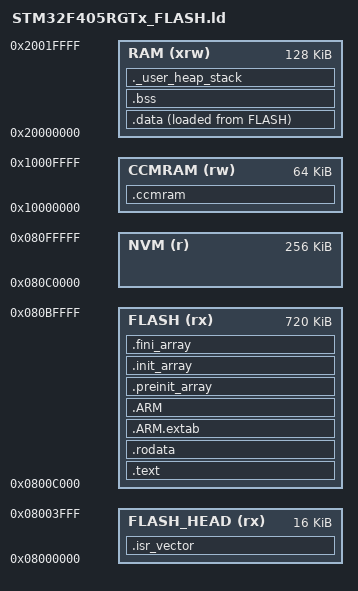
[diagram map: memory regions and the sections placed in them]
/*
*****************************************************************************
**

**  File        : LinkerScript.ld
**
**  Abstract    : Linker script for STM32F405RGTx Device with
**                1024KByte FLASH, 128KByte RAM
**
**                Set heap size, stack size and stack location according
**                to application requirements.
**
**                Set memory bank area and size if external memory is used.
**
**  Target      : STMicroelectronics STM32
**
**
**  Distribution: The file is distributed as is, without any warranty
**                of any kind.
**
**  (c)Copyright Ac6.
**  You may use this file as-is or modify it according to the needs of your
**  project. Distribution of this file (unmodified or modified) is not
**  permitted. Ac6 permit registered System Workbench for MCU users the
**  rights to distribute the assembled, compiled & linked contents of this
**  file as part of an application binary file, provided that it is built
**  using the System Workbench for MCU toolchain.
**
*****************************************************************************
*/

/* Entry Point */
ENTRY(Reset_Handler)

/* Highest address of the user mode stack */
_estack = 0x20020000;    /* end of RAM */
/* Generate a link error if heap and stack don't fit into RAM */
_Min_Heap_Size = 0x3C00;      /* required amount of heap  */
_Min_Stack_Size = 0x800; /* required amount of stack */
_heap_end_max = _estack - _Min_Stack_Size;

/* Specify the memory areas
 *
 * Flash layout no F405 (STM32F405RGT6, 1MB):
 *   sector 0  (16K)  @0x08000000 -> vetores + stub Reset_Handler (FLASH_HEAD)
 *   sector 1  (16K)  @0x08004000 -> ODrive NVM page A (config_manager hardcoded)
 *   sector 2  (16K)  @0x08008000 -> ODrive NVM page B (config_manager hardcoded)
 *   sectores 3-9    @0x0800C000..0x080BFFFF -> .text principal (FLASH)
 *   sector 10 (128K) @0x080C0000 -> FFB EEPROM emulada página 0 (NVM region)
 *   sector 11 (128K) @0x080E0000 -> FFB EEPROM emulada página 1 (NVM region)
 *
 * Phase 3.1: FFB EEPROM mudou de S1+S2 (que colidem com ODrive NVM) pra
 * S10+S11. Defines em Makefile: EEPROM_START_ADDRESS=0x080C0000, PAGE_SIZE=128K.
 */
MEMORY
{
RAM        (xrw) : ORIGIN = 0x20000000, LENGTH = 128K
CCMRAM     (rw)  : ORIGIN = 0x10000000, LENGTH = 64K
FLASH_HEAD (rx)  : ORIGIN = 0x08000000, LENGTH = 16K
FLASH      (rx)  : ORIGIN = 0x0800C000, LENGTH = 720K
NVM        (r)   : ORIGIN = 0x080C0000, LENGTH = 256K
}

/* Define output sections */
SECTIONS
{
  /* Vetores ficam sozinhos no setor 0. DFU bootloader lê SP em +0 e PC em +4. */
  .isr_vector :
  {
    . = ALIGN(4);
    KEEP(*(.isr_vector))
    . = ALIGN(4);
  } >FLASH_HEAD

  /* The program code and other data goes into FLASH */
  .text :
  {
    . = ALIGN(4);
    *(.text)           /* .text sections (code) */
    *(.text*)          /* .text* sections (code) */
    *(.glue_7)         /* glue arm to thumb code */
    *(.glue_7t)        /* glue thumb to arm code */
    *(.eh_frame)

    KEEP (*(.init))
    KEEP (*(.fini))

    . = ALIGN(4);
    _etext = .;        /* define a global symbols at end of code */
  } >FLASH

  /* Constant data goes into FLASH */
  .rodata :
  {
    . = ALIGN(4);
    *(.rodata)         /* .rodata sections (constants, strings, etc.) */
    *(.rodata*)        /* .rodata* sections (constants, strings, etc.) */
    . = ALIGN(4);
  } >FLASH

  .ARM.extab   : { *(.ARM.extab* .gnu.linkonce.armextab.*) } >FLASH
  .ARM : {
    __exidx_start = .;
    *(.ARM.exidx*)
    __exidx_end = .;
  } >FLASH

  .preinit_array     :
  {
    PROVIDE_HIDDEN (__preinit_array_start = .);
    KEEP (*(.preinit_array*))
    PROVIDE_HIDDEN (__preinit_array_end = .);
  } >FLASH
  .init_array :
  {
    PROVIDE_HIDDEN (__init_array_start = .);
    KEEP (*(SORT(.init_array.*)))
    KEEP (*(.init_array*))
    PROVIDE_HIDDEN (__init_array_end = .);
  } >FLASH
  .fini_array :
  {
    PROVIDE_HIDDEN (__fini_array_start = .);
    KEEP (*(SORT(.fini_array.*)))
    KEEP (*(.fini_array*))
    PROVIDE_HIDDEN (__fini_array_end = .);
  } >FLASH

  /* used by the startup to initialize data */
  _sidata = LOADADDR(.data);

  /* Initialized data sections goes into RAM, load LMA copy after code */
  .data : 
  {
    . = ALIGN(4);
    _sdata = .;        /* create a global symbol at data start */
    *(.testdata)
    *(.data)           /* .data sections */
    *(.data*)          /* .data* sections */

    . = ALIGN(4);
    _edata = .;        /* define a global symbol at data end */
  } >RAM AT> FLASH

  _siccmram = LOADADDR(.ccmram);

  /* CCM-RAM section 
  * 
  * IMPORTANT NOTE! 
  * If initialized variables will be placed in this section,
  * the startup code needs to be modified to copy the init-values.
  * Oskar: Added NOLOAD to remove this section from .bin outputs
  */
  .ccmram (NOLOAD):
  {
    . = ALIGN(4);
    _sccmram = .;       /* create a global symbol at ccmram start */
    *(.ccmram)
    *(.ccmram*)
    
    . = ALIGN(4);
    _eccmram = .;       /* create a global symbol at ccmram end */
  } >CCMRAM /*AT> FLASH*/

  
  /* Uninitialized data section */
  . = ALIGN(4);
  .bss :
  {
    /* This is used by the startup in order to initialize the .bss secion */
    _sbss = .;         /* define a global symbol at bss start */
    __bss_start__ = _sbss;
    *(.bss)
    *(.bss*)
    *(COMMON)

    . = ALIGN(4);
    _ebss = .;         /* define a global symbol at bss end */
    __bss_end__ = _ebss;
  } >RAM

  /* User_heap_stack section, used to check that there is enough RAM left */
  ._user_heap_stack :
  {
    . = ALIGN(8);
    PROVIDE ( end = . );
    PROVIDE ( _end = . );
    . = . + _Min_Heap_Size;
    . = . + _Min_Stack_Size;
    . = ALIGN(8);
  } >RAM

  

  /* Remove information from the standard libraries */
  /DISCARD/ :
  {
    libc.a ( * )
    libm.a ( * )
    libgcc.a ( * )
  }

  .ARM.attributes 0 : { *(.ARM.attributes) }
}


